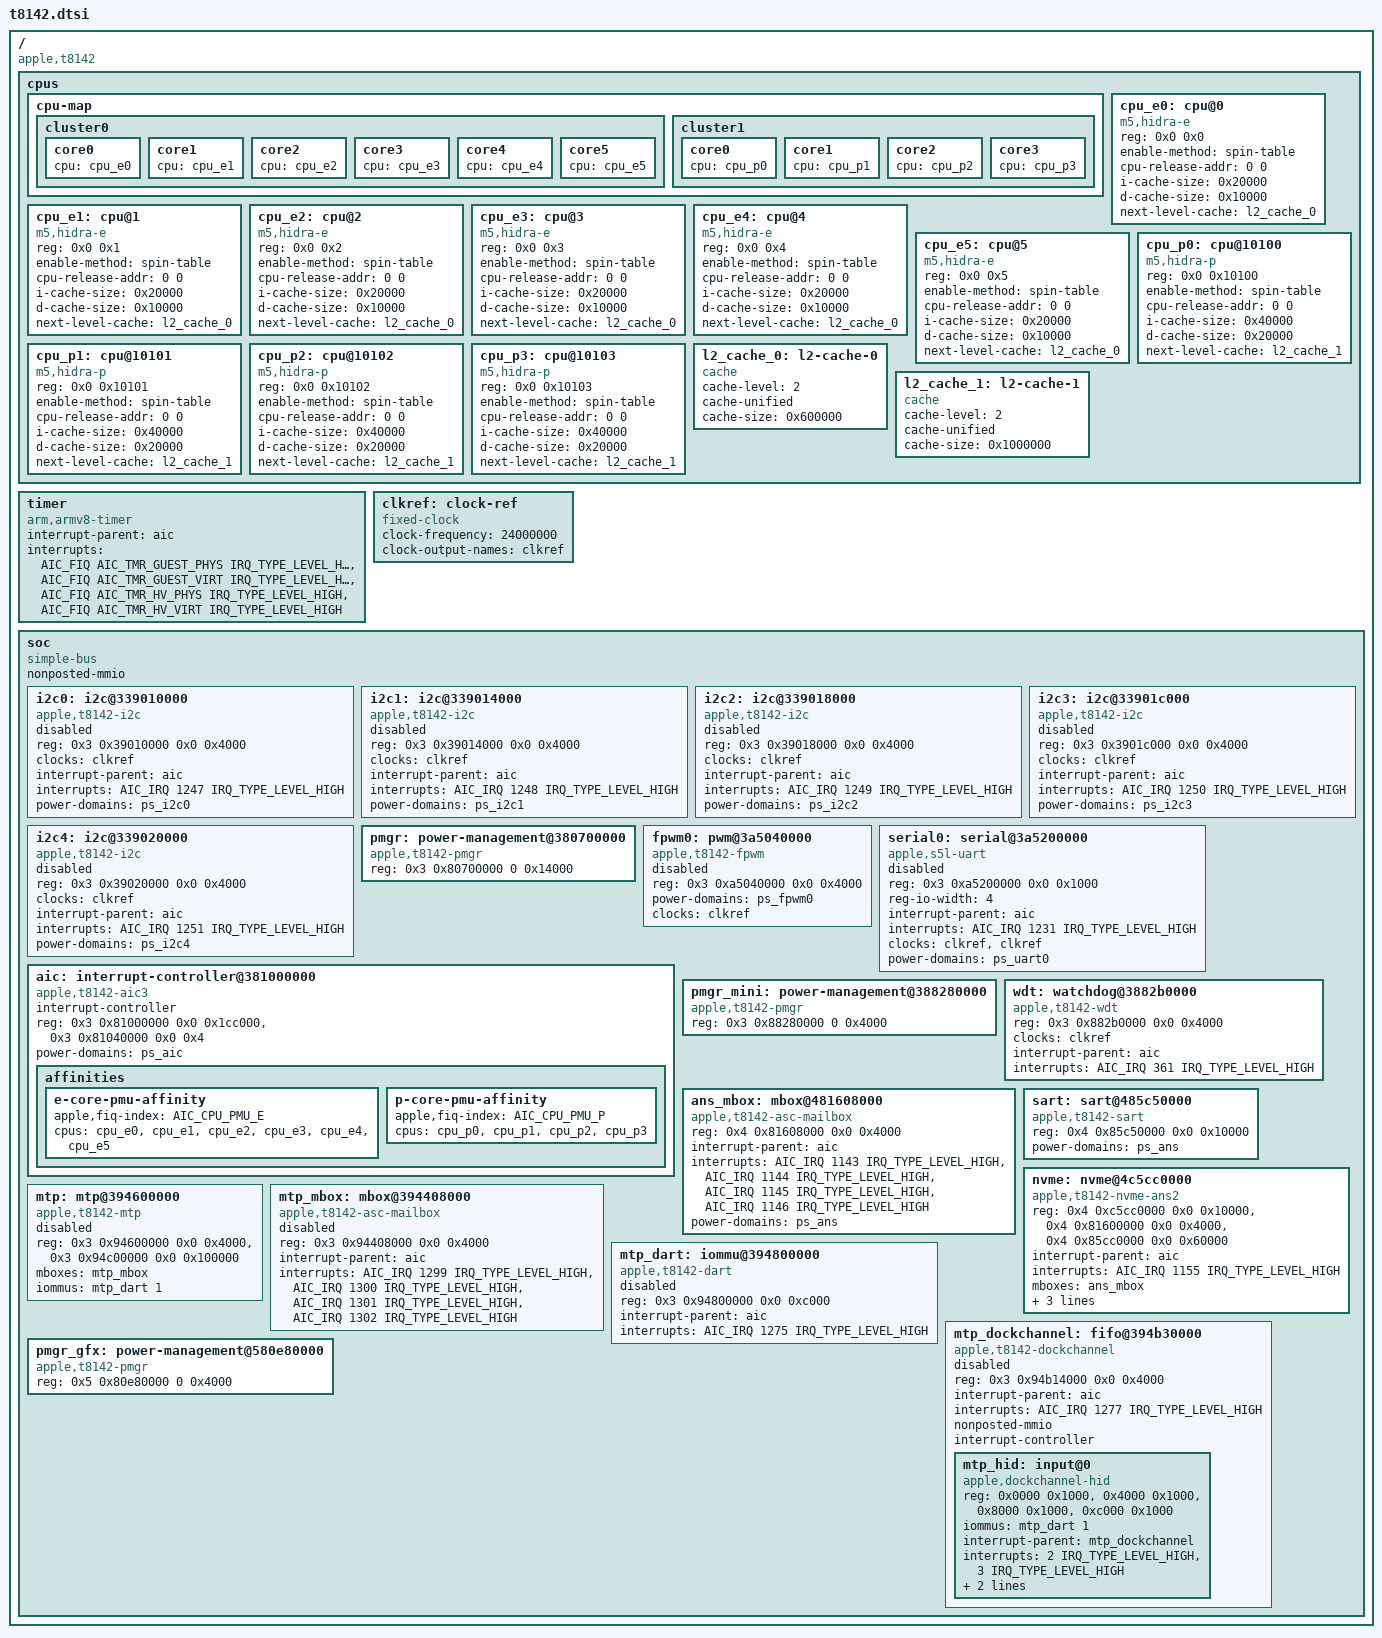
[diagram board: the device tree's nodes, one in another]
// SPDX-License-Identifier: GPL-2.0+ OR MIT
/*
 * Apple T8142 "M5" SoC
 *
 * Other names: H17G
 *
 * Copyright The Asahi Linux Contributors
 */

#include <dt-bindings/gpio/gpio.h>
#include <dt-bindings/interrupt-controller/apple-aic.h>
#include <dt-bindings/interrupt-controller/irq.h>
#include <dt-bindings/pinctrl/apple.h>
#include <dt-bindings/phy/phy.h>
#include <dt-bindings/spmi/spmi.h>

/ {
	compatible = "apple,t8142", "apple,arm-platform";

	#address-cells = <2>;
	#size-cells = <2>;

	cpus {
		#address-cells = <2>;
		#size-cells = <0>;

		cpu-map {
			cluster0 {
				core0 {
					cpu = <&cpu_e0>;
				};
				core1 {
					cpu = <&cpu_e1>;
				};
				core2 {
					cpu = <&cpu_e2>;
				};
				core3 {
					cpu = <&cpu_e3>;
				};
				core4 {
					cpu = <&cpu_e4>;
				};
				core5 {
					cpu = <&cpu_e5>;
				};
			};

			cluster1 {
				core0 {
					cpu = <&cpu_p0>;
				};
				core1 {
					cpu = <&cpu_p1>;
				};
				core2 {
					cpu = <&cpu_p2>;
				};
				core3 {
					cpu = <&cpu_p3>;
				};
			};
		};

		cpu_e0: cpu@0 {
			compatible = "m5,hidra-e";
			device_type = "cpu";
			reg = <0x0 0x0>;
			enable-method = "spin-table";
			cpu-release-addr = <0 0>; 
			i-cache-size = <0x20000>;
			d-cache-size = <0x10000>;
			next-level-cache = <&l2_cache_0>;
		};

		cpu_e1: cpu@1 {
			compatible = "m5,hidra-e";
			device_type = "cpu";
			reg = <0x0 0x1>;
			enable-method = "spin-table";
			cpu-release-addr = <0 0>;
			i-cache-size = <0x20000>;
			d-cache-size = <0x10000>;
			next-level-cache = <&l2_cache_0>;
		};

		cpu_e2: cpu@2 {
			compatible = "m5,hidra-e";
			device_type = "cpu";
			reg = <0x0 0x2>;
			enable-method = "spin-table";
			cpu-release-addr = <0 0>; 
			i-cache-size = <0x20000>;
			d-cache-size = <0x10000>;
			next-level-cache = <&l2_cache_0>;
		};

		cpu_e3: cpu@3 {
			compatible = "m5,hidra-e";
			device_type = "cpu";
			reg = <0x0 0x3>;
			enable-method = "spin-table";
			cpu-release-addr = <0 0>;
			i-cache-size = <0x20000>;
			d-cache-size = <0x10000>;
			next-level-cache = <&l2_cache_0>;
		};

		cpu_e4: cpu@4 {
			compatible = "m5,hidra-e";
			device_type = "cpu";
			reg = <0x0 0x4>;
			enable-method = "spin-table";
			cpu-release-addr = <0 0>; 
			i-cache-size = <0x20000>;
			d-cache-size = <0x10000>;
			next-level-cache = <&l2_cache_0>;
		};

		cpu_e5: cpu@5 {
			compatible = "m5,hidra-e";
			device_type = "cpu";
			reg = <0x0 0x5>;
			enable-method = "spin-table";
			cpu-release-addr = <0 0>; 
			i-cache-size = <0x20000>;
			d-cache-size = <0x10000>;
			next-level-cache = <&l2_cache_0>;
		};

		cpu_p0: cpu@10100 {
			compatible = "m5,hidra-p";
			device_type = "cpu";
			reg = <0x0 0x10100>;
			enable-method = "spin-table";
			cpu-release-addr = <0 0>;
			i-cache-size = <0x40000>;
			d-cache-size = <0x20000>;
			next-level-cache = <&l2_cache_1>;
		};

		cpu_p1: cpu@10101 {
			compatible = "m5,hidra-p";
			device_type = "cpu";
			reg = <0x0 0x10101>;
			enable-method = "spin-table";
			cpu-release-addr = <0 0>; 
			i-cache-size = <0x40000>;
			d-cache-size = <0x20000>;
			next-level-cache = <&l2_cache_1>;

		};

		cpu_p2: cpu@10102 {
			compatible = "m5,hidra-p";
			device_type = "cpu";
			reg = <0x0 0x10102>;
			enable-method = "spin-table";
			cpu-release-addr = <0 0>; /* To be filled by loader */
			i-cache-size = <0x40000>;
			d-cache-size = <0x20000>;
			next-level-cache = <&l2_cache_1>;
		};

		cpu_p3: cpu@10103 {
			compatible = "m5,hidra-p";
			device_type = "cpu";
			reg = <0x0 0x10103>;
			enable-method = "spin-table";
			cpu-release-addr = <0 0>; /* To be filled by loader */
			i-cache-size = <0x40000>;
			d-cache-size = <0x20000>;
			next-level-cache = <&l2_cache_1>;
		};

		l2_cache_0: l2-cache-0 {
			compatible = "cache";
			cache-level = <2>;
			cache-unified;
			cache-size = <0x600000>;
		};

		l2_cache_1: l2-cache-1 {
			compatible = "cache";
			cache-level = <2>;
			cache-unified;
			cache-size = <0x1000000>;
		};
	};

	timer {
		compatible = "arm,armv8-timer";
		interrupt-parent = <&aic>;
		interrupt-names = "phys", "virt", "hyp-phys", "hyp-virt";
		interrupts = <AIC_FIQ AIC_TMR_GUEST_PHYS IRQ_TYPE_LEVEL_HIGH>,
			     <AIC_FIQ AIC_TMR_GUEST_VIRT IRQ_TYPE_LEVEL_HIGH>,
			     <AIC_FIQ AIC_TMR_HV_PHYS IRQ_TYPE_LEVEL_HIGH>,
			     <AIC_FIQ AIC_TMR_HV_VIRT IRQ_TYPE_LEVEL_HIGH>;
	};

	clkref: clock-ref {
		compatible = "fixed-clock";
		#clock-cells = <0>;
		clock-frequency = <24000000>;
		clock-output-names = "clkref";
	};

	soc {
		compatible = "simple-bus";
		#address-cells = <2>;
		#size-cells = <2>;

		ranges;
		nonposted-mmio;

		i2c0: i2c@339010000 {
			compatible = "apple,t8142-i2c", "apple,t8103-i2c";
			reg = <0x3 0x39010000 0x0 0x4000>;
			clocks = <&clkref>;
			interrupt-parent = <&aic>;
			interrupts = <AIC_IRQ 1247 IRQ_TYPE_LEVEL_HIGH>;
			pinctrl-names = "default";
			#address-cells = <0x1>;
			#size-cells = <0x0>;
			power-domains = <&ps_i2c0>;
			status = "disabled";
		};

		i2c1: i2c@339014000 {
			compatible = "apple,t8142-i2c", "apple,t8103-i2c";
			reg = <0x3 0x39014000 0x0 0x4000>;
			clocks = <&clkref>;
			interrupt-parent = <&aic>;
			interrupts = <AIC_IRQ 1248 IRQ_TYPE_LEVEL_HIGH>;
			pinctrl-names = "default";
			#address-cells = <0x1>;
			#size-cells = <0x0>;
			power-domains = <&ps_i2c1>;
			status = "disabled";
		};

		i2c2: i2c@339018000 {
			compatible = "apple,t8142-i2c", "apple,t8103-i2c";
			reg = <0x3 0x39018000 0x0 0x4000>;
			clocks = <&clkref>;
			interrupt-parent = <&aic>;
			interrupts = <AIC_IRQ 1249 IRQ_TYPE_LEVEL_HIGH>;
			pinctrl-names = "default";
			#address-cells = <0x1>;
			#size-cells = <0x0>;
			power-domains = <&ps_i2c2>;
			status = "disabled";
		};

		i2c3: i2c@33901c000 {
			compatible = "apple,t8142-i2c", "apple,t8103-i2c";
			reg = <0x3 0x3901c000 0x0 0x4000>;
			clocks = <&clkref>;
			interrupt-parent = <&aic>;
			interrupts = <AIC_IRQ 1250 IRQ_TYPE_LEVEL_HIGH>;
			pinctrl-names = "default";
			#address-cells = <0x1>;
			#size-cells = <0x0>;
			power-domains = <&ps_i2c3>;
			status = "disabled";
		};

		i2c4: i2c@339020000 {
			compatible = "apple,t8142-i2c", "apple,t8103-i2c";
			reg = <0x3 0x39020000 0x0 0x4000>;
			clocks = <&clkref>;
			interrupt-parent = <&aic>;
			interrupts = <AIC_IRQ 1251 IRQ_TYPE_LEVEL_HIGH>;
			pinctrl-names = "default";
			#address-cells = <0x1>;
			#size-cells = <0x0>;
			power-domains = <&ps_i2c4>;
			status = "disabled";
		};

		pmgr: power-management@380700000 {
			compatible = "apple,t8142-pmgr", "apple,t8103-pmgr", "syscon", "simple-mfd";
			#address-cells = <1>;
			#size-cells = <1>;
			reg = <0x3 0x80700000 0 0x14000>;
			/* child nodes are added in t8142-pmgr.dtsi */
		};


		fpwm0: pwm@3a5040000 {
			compatible = "apple,t8142-fpwm", "apple,s5l-fpwm";
			reg = <0x3 0xa5040000 0x0 0x4000>;
			power-domains = <&ps_fpwm0>;
			clocks = <&clkref>;
			#pwm-cells = <2>;
			status = "disabled";
		};

		serial0: serial@3a5200000 {
			compatible = "apple,s5l-uart";
			reg = <0x3 0xa5200000 0x0 0x1000>;
			reg-io-width = <4>;
			interrupt-parent = <&aic>;
			interrupts = <AIC_IRQ 1231 IRQ_TYPE_LEVEL_HIGH>;
			clocks = <&clkref>, <&clkref>;
			clock-names = "uart", "clk_uart_baud0";
			power-domains = <&ps_uart0>;
			status = "disabled";
		};

		aic: interrupt-controller@381000000 {
			compatible = "apple,t8142-aic3", "apple,t8122-aic3";
			#interrupt-cells = <3>;
			interrupt-controller;
			reg = <0x3 0x81000000 0x0 0x1cc000>,
				<0x3 0x81040000 0x0 0x4>;
			reg-names = "core", "event";
			power-domains = <&ps_aic>;

			affinities {
				e-core-pmu-affinity {
					apple,fiq-index = <AIC_CPU_PMU_E>;
					cpus = <&cpu_e0 &cpu_e1 &cpu_e2 &cpu_e3 &cpu_e4 &cpu_e5>;
				};

				p-core-pmu-affinity {
					apple,fiq-index = <AIC_CPU_PMU_P>;
					cpus = <&cpu_p0 &cpu_p1 &cpu_p2 &cpu_p3>;
				};
			};
		};

		
		pmgr_mini: power-management@388280000 {
			compatible = "apple,t8142-pmgr", "apple,t8103-pmgr", "syscon", "simple-mfd";
			#address-cells = <1>;
			#size-cells = <1>;
			reg = <0x3 0x88280000 0 0x4000>;
			/* child nodes are added in t8142-pmgr.dtsi */
		};

		wdt: watchdog@3882b0000 {
			compatible = "apple,t8142-wdt", "apple,t8103-wdt";
			reg = <0x3 0x882b0000 0x0 0x4000>;
			clocks = <&clkref>;
			interrupt-parent = <&aic>;
			interrupts = <AIC_IRQ 361 IRQ_TYPE_LEVEL_HIGH>;
		};

		ans_mbox: mbox@481608000 {
			compatible = "apple,t8142-asc-mailbox", "apple,asc-mailbox-v4";
			reg = <0x4 0x81608000 0x0 0x4000>;

			interrupt-parent = <&aic>;
			interrupts = <AIC_IRQ 1143 IRQ_TYPE_LEVEL_HIGH>,
			             <AIC_IRQ 1144 IRQ_TYPE_LEVEL_HIGH>,
			             <AIC_IRQ 1145 IRQ_TYPE_LEVEL_HIGH>,
			             <AIC_IRQ 1146 IRQ_TYPE_LEVEL_HIGH>;
			interrupt-names = "send-empty", "send-not-empty",
			                  "recv-empty", "recv-not-empty";

			#mbox-cells = <0>;
			power-domains = <&ps_ans>;
		};

		sart: sart@485c50000 {
			compatible = "apple,t8142-sart", "apple,t6000-sart";
			reg = <0x4 0x85c50000 0x0 0x10000>;
			power-domains = <&ps_ans>;
		};

		nvme: nvme@4c5cc0000 {
			compatible = "apple,t8142-nvme-ans2", "apple,t8132-nvme-ans2";
			reg =	<0x4 0xc5cc0000 0x0 0x10000>,
			    	<0x4 0x81600000 0x0 0x4000>,
			    	<0x4 0x85cc0000 0x0 0x60000>;
			reg-names = "nvme", "ans", "nvmmu";

			interrupt-parent = <&aic>;
			interrupts = <AIC_IRQ 1155 IRQ_TYPE_LEVEL_HIGH>;

			mboxes = <&ans_mbox>;
			apple,sart = <&sart>;

			power-domains = <&ps_ans>, <&ps_apcie_sys_st>;
			power-domain-names = "ans", "apcie0";
			resets = <&ps_ans>;
		};

				
		mtp: mtp@394600000 {
			compatible = "apple,t8142-mtp", "apple,t8142-rtk-helper-asc4", "apple,mtp", "apple,rtk-helper-asc4";
			reg = <0x3 0x94600000 0x0 0x4000>,
				<0x3 0x94c00000 0x0 0x100000>;
			reg-names = "asc", "sram";

			mboxes = <&mtp_mbox>;
			iommus = <&mtp_dart 1>;
			#helper-cells = <0>;

			status = "disabled";
		};

		mtp_mbox: mbox@394408000 {
			compatible = "apple,t8142-asc-mailbox", "apple,asc-mailbox-v4";
			reg = <0x3 0x94408000 0x0 0x4000>;

			interrupt-parent = <&aic>;
			interrupts = <AIC_IRQ 1299 IRQ_TYPE_LEVEL_HIGH>,
				<AIC_IRQ 1300 IRQ_TYPE_LEVEL_HIGH>,
				<AIC_IRQ 1301 IRQ_TYPE_LEVEL_HIGH>,
				<AIC_IRQ 1302 IRQ_TYPE_LEVEL_HIGH>;
			interrupt-names = "send-empty", "send-not-empty",
				"recv-empty", "recv-not-empty";

			#mbox-cells = <0>;
			status = "disabled";
		};

		mtp_dart: iommu@394800000 {
			compatible = "apple,t8142-dart", "apple,t8110-dart";
			reg = <0x3 0x94800000 0x0 0xc000>;

			interrupt-parent = <&aic>;
			interrupts = <AIC_IRQ 1275 IRQ_TYPE_LEVEL_HIGH>;

			#iommu-cells = <1>;

			status = "disabled";
		};

		mtp_dockchannel: fifo@394b30000 {
			compatible = "apple,t8142-dockchannel", "apple,dockchannel";
			reg = <0x3 0x94b14000 0x0 0x4000>;
			reg-names = "irq";
			interrupt-parent = <&aic>;
			interrupts = <AIC_IRQ 1277 IRQ_TYPE_LEVEL_HIGH>;

			ranges = <0 0x3 0x94b28000 0x20000>;
			nonposted-mmio;
			#address-cells = <1>;
			#size-cells = <1>;

			interrupt-controller;
			#interrupt-cells = <2>;

			status = "disabled";

			mtp_hid: input@0 {
				compatible = "apple,dockchannel-hid";
				reg = <0x0000 0x1000>,
				      <0x4000 0x1000>,
				      <0x8000 0x1000>,
				      <0xc000 0x1000>;
				reg-names = "rmt-config", "rmt-data", "config", "data";

				iommus = <&mtp_dart 1>;

				interrupt-parent = <&mtp_dockchannel>;
				interrupts = <2 IRQ_TYPE_LEVEL_HIGH>,
					<3 IRQ_TYPE_LEVEL_HIGH>;
				interrupt-names = "tx", "rx";

				apple,fifo-size = <0x800>;
				apple,helper-cpu = <&mtp>;
			};
		};

		pmgr_gfx: power-management@580e80000 {
			compatible = "apple,t8142-pmgr", "apple,t8103-pmgr", "syscon", "simple-mfd";
			#address-cells = <1>;
			#size-cells = <1>;
			reg = <0x5 0x80e80000 0 0x4000>;
			/* child nodes are added in t8142-pmgr.dtsi */
		};
	};
};

#include "t8142-pmgr.dtsi"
